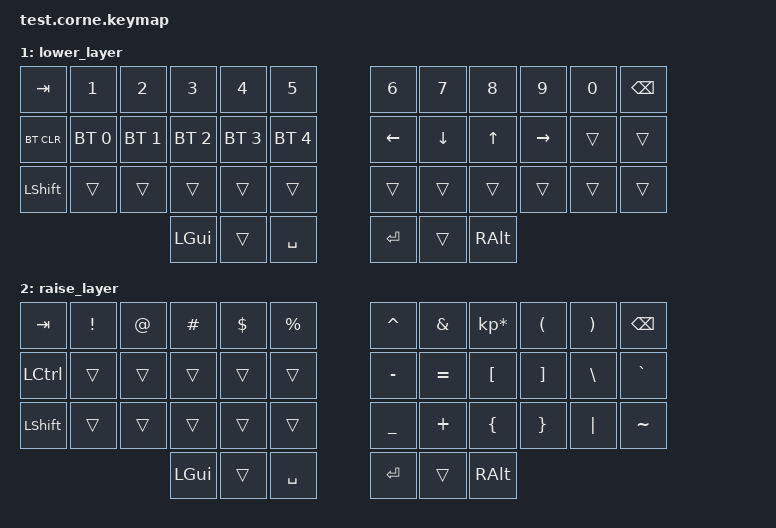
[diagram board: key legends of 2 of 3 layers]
/*
 * Copyright (c) 2020 The ZMK Contributors
 *
 * SPDX-License-Identifier: MIT
 */

#include <behaviors.dtsi>
#include <dt-bindings/zmk/keys.h>
#include <dt-bindings/zmk/bt.h>

/ {
        keymap {
                compatible = "zmk,keymap";

                default_layer {
// -----------------------------------------------------------------------------------------
// |  Y  |  C  |  L  |  M  |  K  |   |  Z  |  F   |  U  |  X  |  '  |
// |  I  |  S  |  R  | T&S |  G  |   |  P  |  N&S |  E  |  A  |  O  |  
// |  Q  |  V  |  W  |  D  |  J  |   |  B  |  H   |LT2&,|  .  |  /  | 
//   | DEL |SPACE&LT1|BSPC&option|   | RET&META | ESC&LT1  |  |
                        bindings = <
   &kp Y &kp C  &kp L &kp M &kp K          &kp Z &kp F &kp U &kp FSLH &kp SQT
   &kp I &kp S  &kp R &mt LSHFT T &kp G    &kp P &mt RSHIFT N &kp E &kp A &kp O
   &kp Q &kp V  &kp W &kp D &kp J          &kp B &kp H &lt 2 COMMA &kp DOT &kp X     
   &kp DEL &lt 1 SPACE  &mt LALT BSPC      &mt RMETA  RET &lt 1 ESC &kp CAPS 
                        >;
                };
                lower_layer {
// -----------------------------------------------------------------------------------------
// |  TAB |  1  |  2  |  3  |  4  |  5  |   |  6  |  7  |  8  |  9  |  0  | BKSP |
// | BTCLR| BT1 | BT2 | BT3 | BT4 | BT5 |   | LFT | DWN |  UP | RGT |     |      |
// | SHFT |     |     |     |     |     |   |     |     |     |     |     |      |
//                    | GUI |     | SPC |   | ENT |     | ALT |
                        bindings = <
   &kp TAB    &kp N1       &kp N2       &kp N3       &kp N4       &kp N5         &kp N6   &kp N7   &kp N8 &kp N9    &kp N0 &kp BSPC
   &bt BT_CLR &bt BT_SEL 0 &bt BT_SEL 1 &bt BT_SEL 2 &bt BT_SEL 3 &bt BT_SEL 4   &kp LEFT &kp DOWN &kp UP &kp RIGHT &trans &trans
   &kp LSHFT  &trans       &trans       &trans       &trans       &trans         &trans   &trans   &trans &trans    &trans &trans
                          	        &kp LGUI     &trans       &kp SPACE      &kp RET  &trans   &kp RALT
                        >;
                };

                raise_layer {
// -----------------------------------------------------------------------------------------
// |  TAB |  !  |  @  |  #  |  $  |  %  |   |  ^  |  &  |  *  |  (  |  )  | BKSP |
// | CTRL |     |     |     |     |     |   |  -  |  =  |  [  |  ]  |  \  |  `   |
// | SHFT |     |     |     |     |     |   |  _  |  +  |  {  |  }  | "|" |  ~   |
//                    | GUI |     | SPC |   | ENT |     | ALT |
                        bindings = <
   &kp  TAB  &kp EXCL &kp AT &kp HASH &kp DLLR &kp PRCNT   &kp CARET &kp AMPS  &kp KP_MULTIPLY &kp LPAR &kp RPAR &kp BSPC
   &kp LCTRL &trans   &trans &trans   &trans   &trans      &kp MINUS &kp EQUAL &kp LBKT        &kp RBKT &kp BSLH &kp GRAVE
   &kp LSHFT &trans   &trans &trans   &trans   &trans      &kp UNDER &kp PLUS  &kp LBRC        &kp RBRC &kp PIPE &kp TILDE
                    	     &kp LGUI &trans   &kp SPACE   &kp RET   &trans    &kp RALT
                        >;
                };
        };
};
